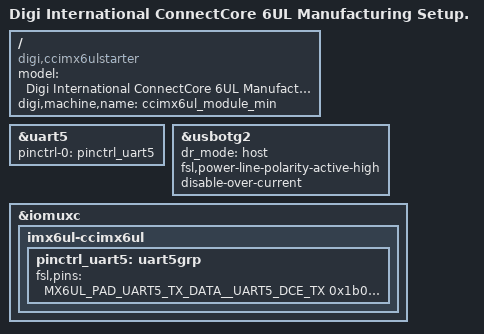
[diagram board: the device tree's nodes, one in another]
/*
 * Copyright 2017 Digi International, Inc.
 *
 * The code contained herein is licensed under the GNU General Public
 * License. You may obtain a copy of the GNU General Public License
 * Version 2 or later at the following locations:
 *
 * http://www.opensource.org/licenses/gpl-license.html
 * http://www.gnu.org/copyleft/gpl.html
 */
/dts-v1/;
#include <dt-bindings/input/input.h>
/* i.MX6 UltraLite CPU */
#include "imx6ul.dtsi"
/* ConnectCore 6UL (wireless/bluetooth variant) */
#include "imx6ul-ccimx6ul.dtsi"

/ {
	model = "Digi International ConnectCore 6UL Manufacturing Setup.";
	compatible = "digi,ccimx6ulstarter", "digi,ccimx6ul", "fsl,imx6ul";
	digi,machine,name = "ccimx6ul_module_min";
};

/* UART5 (Console) */
&uart5 {
	pinctrl-names = "default";
	pinctrl-0 = <&pinctrl_uart5>;
	status = "okay";
};

&usbotg2 {
	dr_mode = "host";
	fsl,power-line-polarity-active-high;
	disable-over-current;
	status = "okay";
};

&iomuxc {
	pinctrl-names = "default";
	
	imx6ul-ccimx6ul {
		pinctrl_uart5: uart5grp {
			fsl,pins = <
			MX6UL_PAD_UART5_TX_DATA__UART5_DCE_TX	0x1b0b1
			MX6UL_PAD_UART5_RX_DATA__UART5_DCE_RX	0x1b0b1
			>;
		};
	};
};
